VERSION ""

NS_ :

BS_:

BU_: PC

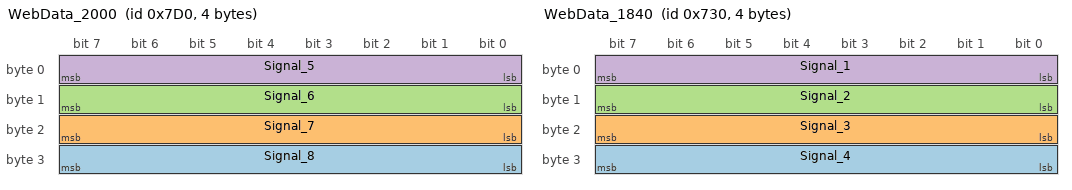
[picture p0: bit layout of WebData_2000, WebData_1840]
BO_ 2000 WebData_2000: 4 Vector__XXX
 SG_ Signal_8 : 24|8@1+ (1,0) [0|255] "" Vector__XXX
 SG_ Signal_7 : 16|8@1+ (1,0) [0|255] "" Vector__XXX
 SG_ Signal_6 : 8|8@1+ (1,0) [0|255] "" Vector__XXX
 SG_ Signal_5 : 0|8@1+ (1,0) [0|255] "" Vector__XXX

BO_ 1840 WebData_1840: 4 PC
 SG_ Signal_4 : 24|8@1+ (1,0) [0|255] "" Vector__XXX
 SG_ Signal_3 : 16|8@1+ (1,0) [0|255] "" Vector__XXX
 SG_ Signal_2 : 8|8@1+ (1,0) [0|255] "" Vector__XXX
 SG_ Signal_1 : 0|8@1+ (1,0) [0|0] "" Vector__XXX

BA_DEF_  "BusType" STRING ;
BA_DEF_DEF_  "BusType" "CAN";
